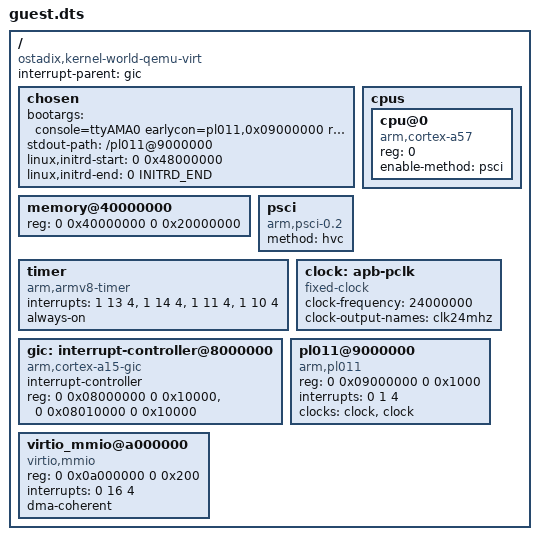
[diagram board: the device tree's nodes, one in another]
/dts-v1/;

/ {
    compatible = "ostadix,kernel-world-qemu-virt";
    #address-cells = <2>;
    #size-cells = <2>;
    interrupt-parent = <&gic>;
    chosen {
        bootargs = "console=ttyAMA0 earlycon=pl011,0x09000000 rdinit=/init panic=-1 loglevel=6";
        stdout-path = "/pl011@9000000";
        linux,initrd-start = <0 0x48000000>;
        linux,initrd-end = <0 INITRD_END>;
    };
    memory@40000000 {
        device_type = "memory";
        reg = <0 0x40000000 0 0x20000000>;
    };
    cpus {
        #address-cells = <1>;
        #size-cells = <0>;
        cpu@0 {
            device_type = "cpu";
            compatible = "arm,cortex-a57";
            reg = <0>;
            enable-method = "psci";
        };
    };
    psci {
        compatible = "arm,psci-0.2";
        method = "hvc";
    };
    timer {
        compatible = "arm,armv8-timer";
        interrupts = <1 13 4>, <1 14 4>, <1 11 4>, <1 10 4>;
        always-on;
    };
    gic: interrupt-controller@8000000 {
        compatible = "arm,cortex-a15-gic";
        #interrupt-cells = <3>;
        #address-cells = <0>;
        interrupt-controller;
        reg = <0 0x08000000 0 0x10000>, <0 0x08010000 0 0x10000>;
    };
    clock: apb-pclk {
        compatible = "fixed-clock";
        #clock-cells = <0>;
        clock-frequency = <24000000>;
        clock-output-names = "clk24mhz";
    };
    pl011@9000000 {
        compatible = "arm,pl011", "arm,primecell";
        reg = <0 0x09000000 0 0x1000>;
        interrupts = <0 1 4>;
        clocks = <&clock>, <&clock>;
        clock-names = "uartclk", "apb_pclk";
    };
    virtio_mmio@a000000 {
        compatible = "virtio,mmio";
        reg = <0 0x0a000000 0 0x200>;
        interrupts = <0 16 4>;
        dma-coherent;
    };
};
